# MB9AFA4xN register map
File version: 1.7
Registers are 32-bit, read-write, reset 0x0 unless marked. A register's access mark holds for its fields unless they carry their own. Offsets are from the block's base; [hi:lo] are bit positions; {n}, {i} and the like mark numbered series.

## WC — Watch Counter
Base 0x4003A000
0x00 WCRD 8-bit ro — Watch Counter Read Register
  [5:0] CTR — counter value
0x01 WCRL 8-bit — Watch Counter Reload Register
  [5:0] RLC — reload value
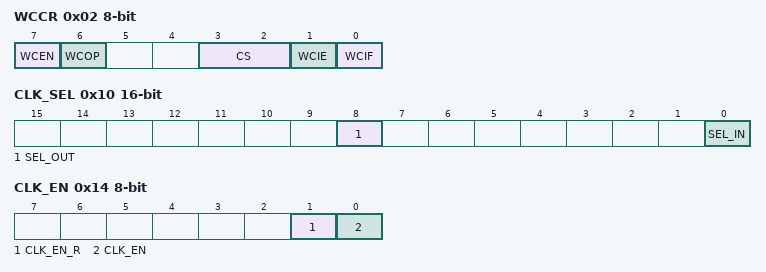
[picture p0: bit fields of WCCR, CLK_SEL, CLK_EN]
0x02 WCCR 8-bit — Watch Counter Control Register
  [7] WCEN — Watch counter operation enable bit
  [6] WCOP ro — Watch counter operating state flag
  [3:2] CS — Count clock select bits
  [1] WCIE — Interrupt request enable bit
  [0] WCIF — Interrupt request flag bit
0x10 CLK_SEL 16-bit — Clock Selection Register
  [8] SEL_OUT — Output clock selection bit
  [0] SEL_IN — Input clock selection bit
0x14 CLK_EN 8-bit — Division Clock Enable Register
  [1] CLK_EN_R — Division clock enable read bit
  [0] CLK_EN — Division clock enable bit

## EXTI — External Interrupt and NMI Control
Base 0x40030000
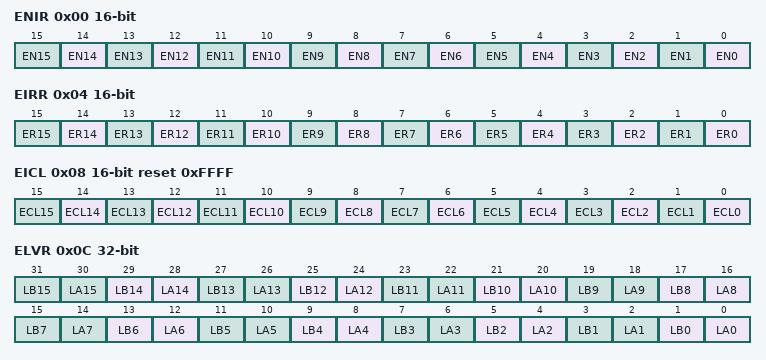
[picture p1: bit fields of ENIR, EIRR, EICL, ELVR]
0x00 ENIR 16-bit — Enable Interrupt Request Register
  [n] EN{n} (n=0..15) — Bit{n} of ENIR
0x04 EIRR 16-bit ro reset not defined — External Interrupt Request Register
  [n] ER{n} (n=0..15) — Bit{n} of EIRR
0x08 EICL 16-bit reset 0xFFFF — External Interrupt Clear Register
  [n] ECL{n} (n=0..15) — Bit{n} of EICL
0x0C ELVR — External Interrupt Level Register
  [2n+1] LB{n} (n=0..15) — Bit{2n+1} of ELVR
  [2n] LA{n} (n=0..15) — Bit{2n} of ELVR
0x14 NMIRR 8-bit ro — Non Maskable Interrupt Request Register
  [0] NR — NMI interrupt request detection bit
0x18 NMICL 8-bit reset 0x1 — Non Maskable Interrupt Clear Register
  [0] NCL — NMI interrupt cause clear bit

## LCDC — LCD Controller
Base 0x40032000
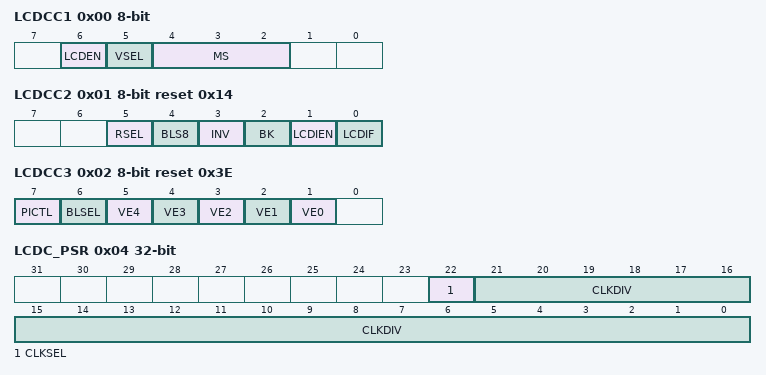
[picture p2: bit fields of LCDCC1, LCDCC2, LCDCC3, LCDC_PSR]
0x00 LCDCC1 8-bit — LCDC Control Register 1
  [6] LCDEN — Timer mode operation enable bit
  [5] VSEL — LCD drive power control bit
  [4:2] MS — LCD controller display mode selection bits
0x01 LCDCC2 8-bit reset 0x14 — LCDC Control Register 2
  [5] RSEL — Divider resistor value selection bit
  [4] BLS8 — 8 COM mode bias selection bit
  [3] INV — Reverse display control bit
  [2] BK — Blank display control bit
  [1] LCDIEN — Interrupt enable bit
  [0] LCDIF — Interrupt request detection bit
0x02 LCDCC3 8-bit reset 0x3E — LCDC Control Register 3
  [7] PICTL — I/O port input control bit
  [6] BLSEL — Blink interval selection bit
  [n+1] VE{n} (n=0..4) — VV{n} selection bit
0x04 LCDC_PSR — LCDC Clock Prescaler Register
  [22] CLKSEL — Source clock selection bit
  [21:0] CLKDIV — LCDC clock division ratio setting bit
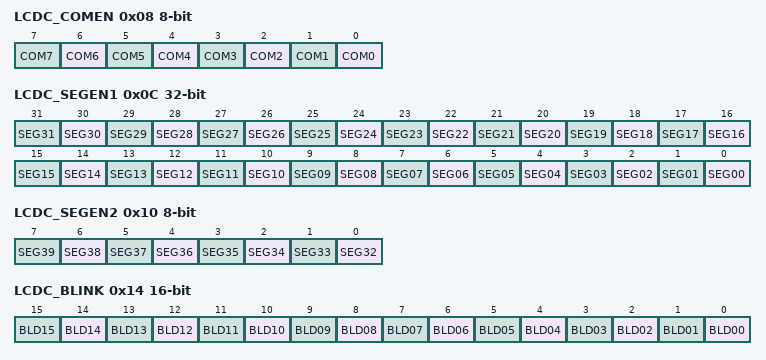
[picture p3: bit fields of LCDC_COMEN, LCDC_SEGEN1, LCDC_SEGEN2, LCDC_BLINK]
0x08 LCDC_COMEN 8-bit — LCDC COM Output Enable Register
  [n] COM{n} (n=4..7) — Dual purpose COM/SEG port control bits
  [n] COM{n} (n=0..3) — Dual purpose COM port control bit
0x0C LCDC_SEGEN1 — LCDC SEG Output Enable Register 1
  [n] SEG{n:02} (n=0..31) — Segment {n}
0x10 LCDC_SEGEN2 8-bit — LCDC SEG Output Enable Register 2
  [n-32] SEG{n} (n=32..39) — Segment {n}
0x14 LCDC_BLINK 16-bit — LCDC Blink Setting Register
  [n] BLD{n:02} (n=0..15) — Blink operation control bit {n}
{0x1C+i} LCDRAM{i:02} 8-bit (i=0..39) — Display Data Memory Register {i:02}
  [7:0] LCDRAM — Display Data {i:02}

## HDMICEC0 — HDMI-CEC ch.0
Base 0x40034000
Same registers: HDMICEC1 0x40034100
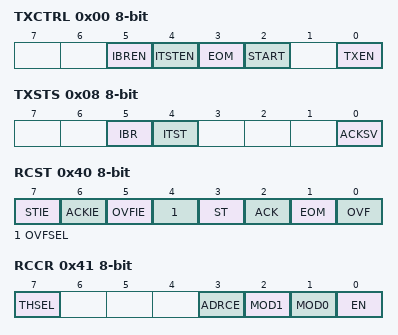
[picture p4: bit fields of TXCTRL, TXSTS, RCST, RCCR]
0x00 TXCTRL 8-bit — Transmission Control Register
  [5] IBREN — Bus error detection interrupt enable bit
  [4] ITSTEN — transmission status interrupt enable bit
  [3] EOM — EOM setting bit
  [2] START — START setting bit
  [0] TXEN — Transmission operation enable bit
0x04 TXDATA 8-bit — Transmission Data Register
  [7:0] TXDATA — Transmission Data
0x08 TXSTS 8-bit — Transmission Status Register
  [5] IBR — Bus error detection interrupt request bit
  [4] ITST — Transmission status interrupt request bit
  [0] ACKSV — ACK cycle value bit
0x0C SFREE 8-bit — Signal Free Time Setting Register
  [3:0] SFREE — Signal free time setting bits
0x40 RCST 8-bit — Reception Interrupt Control Register
  [7] STIE — Start bit interrupt enable bit
  [6] ACKIE — ACK interrupt enable bit
  [5] OVFIE — Counter overflow interrupt enable bit
  [4] OVFSEL — Counter overflow detection condition setting bit
  [3] ST — Start bit detection bit
  [2] ACK — ACK: ACK detection bit
  [1] EOM — EOM detection bit
  [0] OVF — Counter overflow detection bit
0x41 RCCR 8-bit — Reception Control Register
  [7] THSEL — Threshold selection bit
  [3] ADRCE — Address comparison enable bit
  [2] MOD1 — Operation mode setting bits
  [1] MOD0 — Operation mode setting bits
  [0] EN — Operation enable bit
0x44 RCDAHW 8-bit — "H" Width Setting Register A
  [7:0] RCDAHW — "H" Width Setting A
0x45 RCSHW 8-bit — Start Bit "H" Width Setting Register
  [7:0] RCSHW — Start Bit "H" Width Setting
0x49 RCDBHW 8-bit — "H" Width Setting Register B
  [7:0] RCDBHW — "H" Width Setting B
0x4C RCADR2 8-bit — Device Address Setting Register 2
  [4:0] RCADR2 — Device Address 2
0x4D RCADR1 8-bit — Device Address Setting Register 1
  [4:0] RCADR1 — Device Address 1
0x50 RCDTHL 8-bit ro — Data Save Register (High-Low)
0x51 RCDTHH 8-bit ro — Data Save Register (High-High)
0x54 RCDTLL 8-bit ro — Data Save Register (Low-Low)
0x55 RCDTLH 8-bit ro — Data Save Register (Low-High)
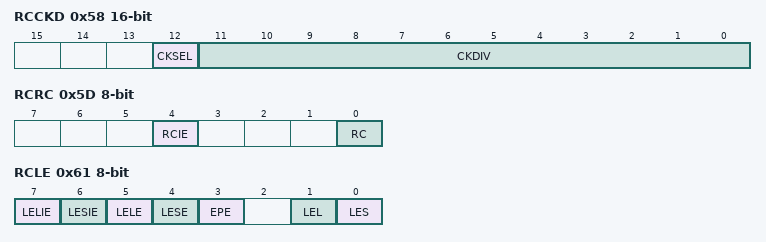
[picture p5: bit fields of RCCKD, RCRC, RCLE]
0x58 RCCKD 16-bit — Clock Division Setting Register
  [12] CKSEL — Operating clock selection bit
  [11:0] CKDIV — Operating clock division setting bits
0x5C RCRHW 8-bit — Repeat Code "H" Width Setting Register
  [7:0] RCRHW — "Repeat code "H" width setting bits"
0x5D RCRC 8-bit — Repeat Code Interrupt Control Register
  [4] RCIE — Repeat Code Interrupt enable bit
  [0] RC — Repeat code detection flag bit
0x61 RCLE 8-bit — Data Bit Width Violation Control Register
  [7] LELIE — Maximum data bit width violation interrupt enable bit
  [6] LESIE — Minimum data bit width violation interrupt enable bit
  [5] LELE — Maximum data bit width violation detection enable bit
  [4] LESE — Minimum data bit width violation detection enable bit
  [3] EPE — Error pulse output enable bit
  [1] LEL — Maximum data bit width violation detection flag bit
  [0] LES — Minimum data bit width violation detection flag bit
0x64 RCLESW 8-bit — Minimum Data Bit Width Setting Register
  [7:0] RCLESW — Minimum data bit width setting bits
0x65 RCLELW 8-bit — Maximum Data Bit Width Setting Register
  [7:0] RCLELW — Maximum data bit width setting bits

## Notices in the file
Licence Terms
FUJITSU SEMICONDUCTOR LIMITED (gLICENSORh) hereby grants and
you (gLICENSEEh) hereby accept a non transferable, non-exclusive
licence to use and copy the deliverables (gDeliverablesh) solely for
the purpose of; (i) developing LICENSEEfs development tools and
distributing such development tools to third parties; (ii) generating
derivative representations of the Deliverables to develop and debug
software for LICENSORfs targeted devices or device series identified
within the Deliverables, (together the gPurposeh) under the following
terms and conditions:
1. Ownership.
The Deliverables are the property of LICENSOR. LICENSEE acquires no
right, title or interest in the Deliverables other than the licence
rights granted herein.
2. Use.
LICENSEE shall only be permitted to use the Deliverables for the
Purpose. LICENSEE shall not reverse engineer, decompile or
disassemble the Deliverables, in whole or in part.
3. Copies.
All copies of the Deliverables must bear the same notice(s) contained
on the original copies of the Deliverables.
4. No Warranty.
THE DELIVERABLES ARE PROVIDED gAS ISh AND ANY EXPRESS, IMPLIED OR
STATUTORY WARRANTIES, INCLUDING, BUT NOT LIMITED TO, THE IMPLIED
WARRANTIES OF MERCHANTABILITY, SATISFACTORY QUALITY AND FITNESS FOR
A PARTICULAR PURPOSE ARE DISCLAIMED.
IN NO EVENT SHALL LICENSOR BE LIABLE FOR ANY DIRECT, INDIRECT,
INCIDENTAL, SPECIAL, EXEMPLARY, OR CONSEQUENTIAL DAMAGES HOWEVER CAUSED
AND ON ANY THEORY OF LIABILITY, WHETHER IN CONTRACT, STRICT LIABILITY,
OR TORT (INCLUDING NEGLIGENCE OR OTHERWISE) ARISING IN ANY WAY OUT OF
THE USE OF THE DELIVERABLES, EVEN IF ADVISED OF THE POSSIBILITY OF SUCH
DAMAGE.
LICENSEE EXPRESSLY ASSUMES ALL LIABILITIES AND RISKS, FOR USE OR
OPERATION OF THE DELIVERABLES.
5.In the event that LICENSEE receives early access to the Deliverables,
LICENSEE acknowledges and agrees that;
(a) notwithstanding the licence grants above, LICENSEE shall only be
permitted to use the Deliverables solely internally for evaluation and
providing feedback to LICENSOR;
(b) except with respect to the limited licence grants in 5(a), LICENSEE
shall be subject to all of the terms and conditions set out above; and
(c) the Deliverables are confidential information and LICENSEE shall
maintain in confidence the Deliverables and apply security measures no
less stringent than the measures that LICENSEE applies to its own like
information, but not less than a reasonable degree of care, to prevent
unauthorised disclosure and use of the Deliverables.
